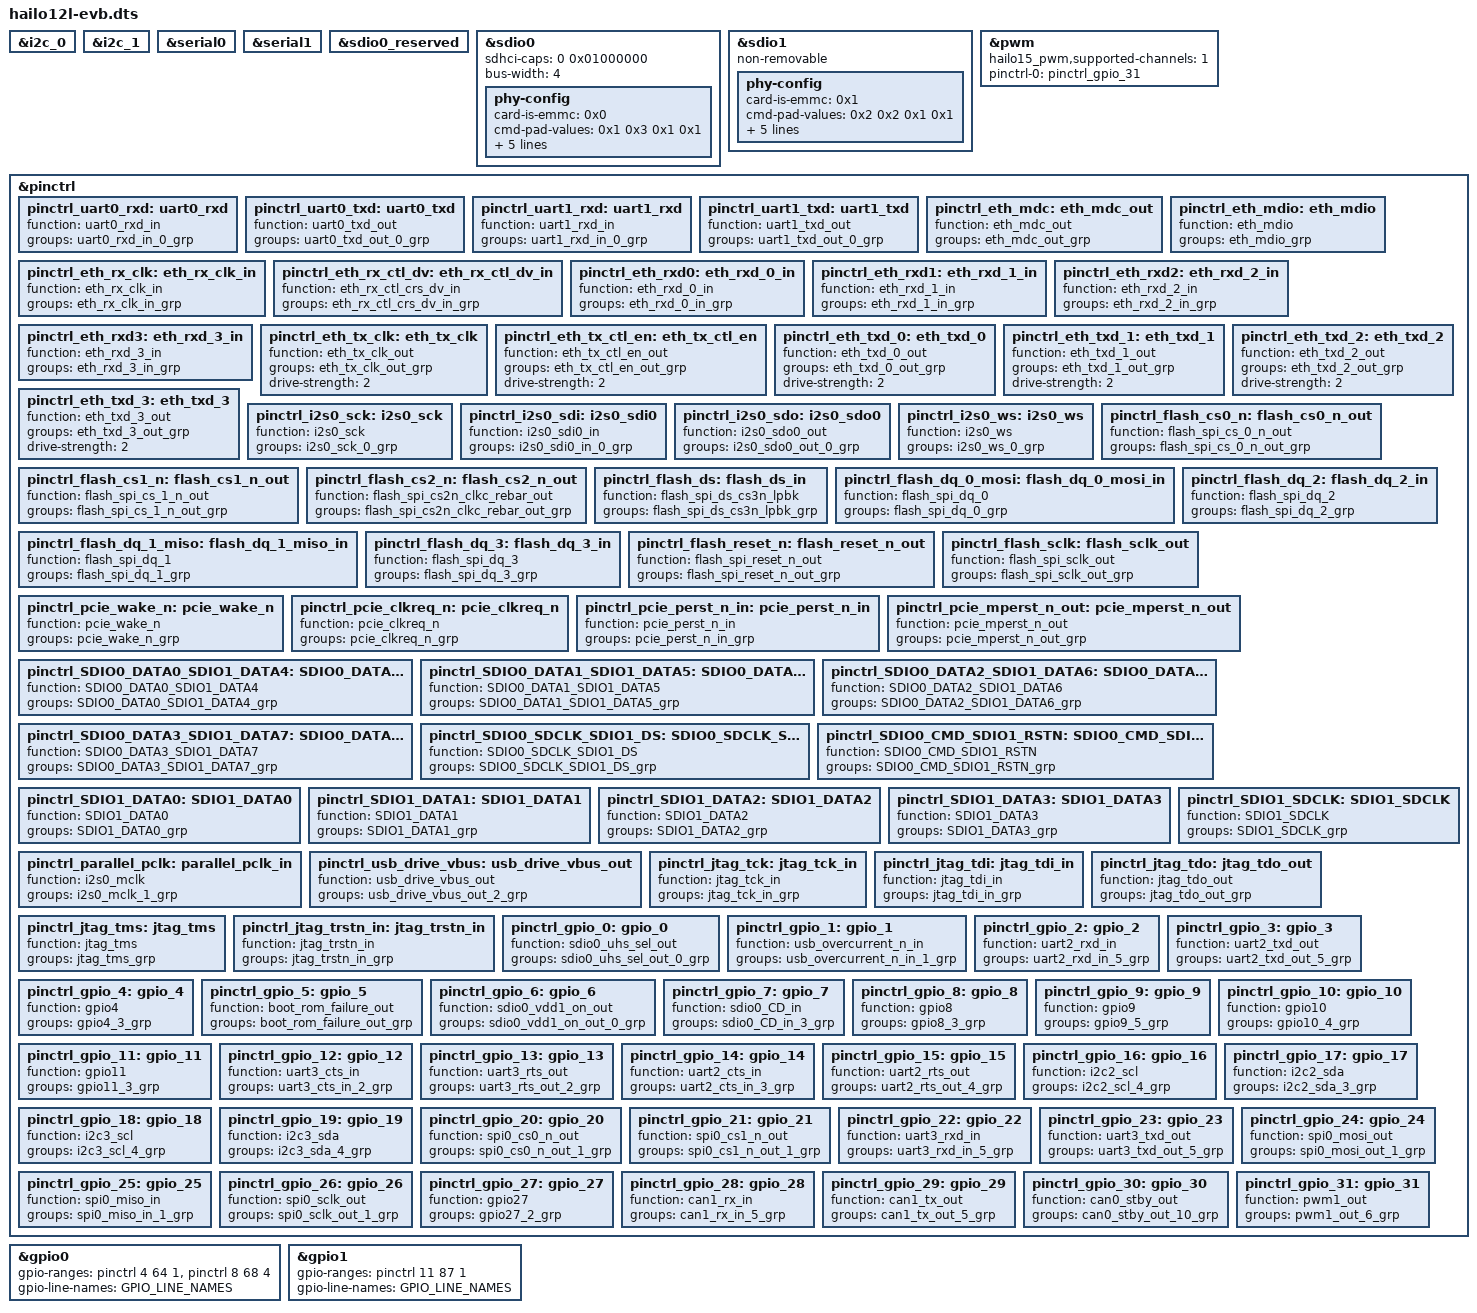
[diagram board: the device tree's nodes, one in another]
// SPDX-License-Identifier:     GPL-2.0
/*
 * Copyright (c) 2019-2025 Hailo Technologies Ltd. All rights reserved.
 */

/dts-v1/;
#include "hailo12l-base.dtsi"

&i2c_0 {
    status = "okay";
};

&i2c_1 {
    status = "okay";
};

&serial0 {
    status = "okay";
};

&serial1 {
    status = "okay";
};

&sdio0_reserved {
    status = "okay";
};

&sdio0 {
    status = "okay";
    sdhci-caps = <0 0x01000000>; // Force VOLT33 capability
    bus-width = <4>;
    phy-config {
            card-is-emmc = <0x0>;
            cmd-pad-values = <0x1 0x3 0x1 0x1>; // txslew_ctrl_n, txslew_ctrl_p, weakpull_enable, rxsel
            dat-pad-values = <0x1 0x3 0x1 0x1>; // txslew_ctrl_n, txslew_ctrl_p, weakpull_enable, rxsel
            rst-pad-values = <0x1 0x3 0x1 0x1>; // txslew_ctrl_n, txslew_ctrl_p, weakpull_enable, rxsel
            clk-pad-values = <0x1 0x3 0x0 0x1>; // txslew_ctrl_n, txslew_ctrl_p, weakpull_enable, rxsel
            sdclkdl-cnfg = <0x1 0x7F>; //extdly_en, cckdl_dc
            drive-strength = <0x9 0x8>; //pad_sp, pad_sn
    };
};

&sdio1 {
    status = "okay";
    non-removable;
    phy-config {
            card-is-emmc = <0x1>;
            cmd-pad-values = <0x2 0x2 0x1 0x1>; // txslew_ctrl_n, txslew_ctrl_p, weakpull_enable, rxsel
            dat-pad-values = <0x2 0x2 0x1 0x1>; // txslew_ctrl_n, txslew_ctrl_p, weakpull_enable, rxsel
            rst-pad-values = <0x2 0x2 0x1 0x1>; // txslew_ctrl_n, txslew_ctrl_p, weakpull_enable, rxsel
            clk-pad-values = <0x2 0x2 0x0 0x0>; // txslew_ctrl_n, txslew_ctrl_p, weakpull_enable, rxsel
            sdclkdl-cnfg = <0x1 0x59>; //extdly_en, cckdl_dc
            drive-strength = <0x9 0x8>; //pad_sp, pad_sn
            u-boot,dm-spl;
    };
};

&pwm {
    status = "okay";
    hailo15_pwm,supported-channels = <1>;
    pinctrl-names = "default";
    pinctrl-0 = <&pinctrl_gpio_31>;
};

&pinctrl {
    /* IO_PAD_0  - I2C0_SCL - non-muxable */
    /* IO_PAD_1  - I2C0_SDA - non-muxable */
    /* IO_PAD_2  - I2C1_SCL - non-muxable */
    /* IO_PAD_3  - I2C1_SDA - non-muxable */

    /* IO_PAD_4 */
    pinctrl_uart0_rxd: uart0_rxd {
        function = "uart0_rxd_in";
        groups = "uart0_rxd_in_0_grp";
    };

    /* IO_PAD_5 */
    pinctrl_uart0_txd: uart0_txd {
        function = "uart0_txd_out";
        groups = "uart0_txd_out_0_grp";
    };

    /* IO_PAD_6 */
    pinctrl_uart1_rxd: uart1_rxd {
        function = "uart1_rxd_in";
        groups = "uart1_rxd_in_0_grp";
    };

    /* IO_PAD_7 */
    pinctrl_uart1_txd: uart1_txd {
        function = "uart1_txd_out";
        groups = "uart1_txd_out_0_grp";
    };

    /* IO_PAD_8 */
    pinctrl_eth_mdc: eth_mdc_out {
        function = "eth_mdc_out";
        groups = "eth_mdc_out_grp";
    };

    /* IO_PAD_9 */
    pinctrl_eth_mdio: eth_mdio {
        function = "eth_mdio";
        groups = "eth_mdio_grp";
    };

    /* IO_PAD_10 */
    pinctrl_eth_rx_clk: eth_rx_clk_in {
        function = "eth_rx_clk_in";
        groups = "eth_rx_clk_in_grp";
    };

    /* IO_PAD_11 */
    pinctrl_eth_rx_ctl_dv: eth_rx_ctl_dv_in {
        function = "eth_rx_ctl_crs_dv_in";
        groups = "eth_rx_ctl_crs_dv_in_grp";
    };

    /* IO_PAD_12 */
    pinctrl_eth_rxd0: eth_rxd_0_in {
        function = "eth_rxd_0_in";
        groups = "eth_rxd_0_in_grp";
    };

    /* IO_PAD_13 */
    pinctrl_eth_rxd1: eth_rxd_1_in {
        function = "eth_rxd_1_in";
        groups = "eth_rxd_1_in_grp";
    };

    /* IO_PAD_14 */
    pinctrl_eth_rxd2: eth_rxd_2_in {
        function = "eth_rxd_2_in";
        groups = "eth_rxd_2_in_grp";
    };

    /* IO_PAD_15 */
    pinctrl_eth_rxd3: eth_rxd_3_in {
        function = "eth_rxd_3_in";
        groups = "eth_rxd_3_in_grp";
    };

    /* IO_PAD_16 */
    pinctrl_eth_tx_clk: eth_tx_clk {
        function = "eth_tx_clk_out";
        groups = "eth_tx_clk_out_grp";
        drive-strength = <2>;
    };

    /* IO_PAD_17 */
    pinctrl_eth_tx_ctl_en: eth_tx_ctl_en {
        function = "eth_tx_ctl_en_out";
        groups = "eth_tx_ctl_en_out_grp";
        drive-strength = <2>;
    };

    /* IO_PAD_18 */
    pinctrl_eth_txd_0: eth_txd_0 {
        function = "eth_txd_0_out";
        groups = "eth_txd_0_out_grp";
        drive-strength = <2>;
    };

    /* IO_PAD_19 */
    pinctrl_eth_txd_1: eth_txd_1 {
        function = "eth_txd_1_out";
        groups = "eth_txd_1_out_grp";
        drive-strength = <2>;
    };

    /* IO_PAD_20 */
    pinctrl_eth_txd_2: eth_txd_2 {
        function = "eth_txd_2_out";
        groups = "eth_txd_2_out_grp";
        drive-strength = <2>;
    };

    /* IO_PAD_21 */
    pinctrl_eth_txd_3: eth_txd_3 {
        function = "eth_txd_3_out";
        groups = "eth_txd_3_out_grp";
        drive-strength = <2>;
    };

    /* IO_PAD_22 */
    pinctrl_i2s0_sck: i2s0_sck {
        function = "i2s0_sck";
        groups = "i2s0_sck_0_grp";
    };

    /* IO_PAD_23 */
    pinctrl_i2s0_sdi: i2s0_sdi0 {
        function = "i2s0_sdi0_in";
        groups = "i2s0_sdi0_in_0_grp";
    };

    /* IO_PAD_24 */
    pinctrl_i2s0_sdo: i2s0_sdo0 {
        function = "i2s0_sdo0_out";
        groups = "i2s0_sdo0_out_0_grp";
    };

    /* IO_PAD_25 */
    pinctrl_i2s0_ws: i2s0_ws {
        function = "i2s0_ws";
        groups = "i2s0_ws_0_grp";
    };

    /* IO_PAD_26 */
	pinctrl_flash_cs0_n: flash_cs0_n_out {
	    function = "flash_spi_cs_0_n_out";
        groups = "flash_spi_cs_0_n_out_grp";
    };

    /* IO_PAD_27 */
    pinctrl_flash_cs1_n: flash_cs1_n_out {
	    function = "flash_spi_cs_1_n_out";
        groups = "flash_spi_cs_1_n_out_grp";
    };

    /* IO_PAD_28 */
    pinctrl_flash_cs2_n: flash_cs2_n_out {
	    function = "flash_spi_cs2n_clkc_rebar_out";
        groups = "flash_spi_cs2n_clkc_rebar_out_grp";
    };

    /* IO_PAD_29 */
    pinctrl_flash_ds: flash_ds_in {
	    function = "flash_spi_ds_cs3n_lpbk";
        groups = "flash_spi_ds_cs3n_lpbk_grp";
    };

    /* IO_PAD_30 */
    pinctrl_flash_dq_0_mosi: flash_dq_0_mosi_in {
	    function = "flash_spi_dq_0";
        groups = "flash_spi_dq_0_grp";
    };

    /* IO_PAD_31 */
    pinctrl_flash_dq_1_miso: flash_dq_1_miso_in {
	    function = "flash_spi_dq_1";
        groups = "flash_spi_dq_1_grp";
    };

    /* IO_PAD_32 */
    pinctrl_flash_dq_2: flash_dq_2_in {
	    function = "flash_spi_dq_2";
        groups = "flash_spi_dq_2_grp";
    };

    /* IO_PAD_33 */
    pinctrl_flash_dq_3: flash_dq_3_in {
	    function = "flash_spi_dq_3";
        groups = "flash_spi_dq_3_grp";
    };

    /* IO_PAD_34 */
    pinctrl_flash_reset_n: flash_reset_n_out {
	    function = "flash_spi_reset_n_out";
        groups = "flash_spi_reset_n_out_grp";
    };

    /* IO_PAD_35 */
    pinctrl_flash_sclk: flash_sclk_out {
	    function = "flash_spi_sclk_out";
        groups = "flash_spi_sclk_out_grp";
    };

    /* IO_PAD_36 */
    pinctrl_pcie_wake_n: pcie_wake_n {
        function = "pcie_wake_n";
        groups = "pcie_wake_n_grp";
    };

    /* IO_PAD_37 */
    pinctrl_pcie_clkreq_n: pcie_clkreq_n {
        function = "pcie_clkreq_n";
        groups = "pcie_clkreq_n_grp";
    };

    /* IO_PAD_38 */
    pinctrl_pcie_perst_n_in: pcie_perst_n_in {
        function = "pcie_perst_n_in";
        groups = "pcie_perst_n_in_grp";
    };

    /* IO_PAD_39 */
    pinctrl_pcie_mperst_n_out: pcie_mperst_n_out {
        function = "pcie_mperst_n_out";
        groups = "pcie_mperst_n_out_grp";
    };

    /* IO_PAD_40 */
    pinctrl_SDIO0_DATA0_SDIO1_DATA4: SDIO0_DATA0_SDIO1_DATA4 {
        function = "SDIO0_DATA0_SDIO1_DATA4";
        groups = "SDIO0_DATA0_SDIO1_DATA4_grp";
    };

    /* IO_PAD_41 */
    pinctrl_SDIO0_DATA1_SDIO1_DATA5: SDIO0_DATA1_SDIO1_DATA5 {
        function = "SDIO0_DATA1_SDIO1_DATA5";
        groups = "SDIO0_DATA1_SDIO1_DATA5_grp";
    };

    /* IO_PAD_42 */
    pinctrl_SDIO0_DATA2_SDIO1_DATA6: SDIO0_DATA2_SDIO1_DATA6 {
        function = "SDIO0_DATA2_SDIO1_DATA6";
        groups = "SDIO0_DATA2_SDIO1_DATA6_grp";
    };

    /* IO_PAD_43 */
    pinctrl_SDIO0_DATA3_SDIO1_DATA7: SDIO0_DATA3_SDIO1_DATA7 {
        function = "SDIO0_DATA3_SDIO1_DATA7";
        groups = "SDIO0_DATA3_SDIO1_DATA7_grp";
    };

    /* IO_PAD_44 */
    pinctrl_SDIO0_SDCLK_SDIO1_DS: SDIO0_SDCLK_SDIO1_DS {
        function = "SDIO0_SDCLK_SDIO1_DS";
        groups = "SDIO0_SDCLK_SDIO1_DS_grp";
    };

    /* IO_PAD_45 */
    pinctrl_SDIO0_CMD_SDIO1_RSTN: SDIO0_CMD_SDIO1_RSTN {
        function = "SDIO0_CMD_SDIO1_RSTN";
        groups = "SDIO0_CMD_SDIO1_RSTN_grp";
    };

    /* IO_PAD_46 */
    pinctrl_SDIO1_DATA0: SDIO1_DATA0 {
        function = "SDIO1_DATA0";
        groups = "SDIO1_DATA0_grp";
    };

    /* IO_PAD_47 */
    pinctrl_SDIO1_DATA1: SDIO1_DATA1 {
        function = "SDIO1_DATA1";
        groups = "SDIO1_DATA1_grp";
    };

    /* IO_PAD_48 */
    pinctrl_SDIO1_DATA2: SDIO1_DATA2 {
        function = "SDIO1_DATA2";
        groups = "SDIO1_DATA2_grp";
    };

    /* IO_PAD_49 */
    pinctrl_SDIO1_DATA3: SDIO1_DATA3 {
        function = "SDIO1_DATA3";
        groups = "SDIO1_DATA3_grp";
    };

    /* IO_PAD_50 - SDIO1_CMD - non-muxable */

    /* IO_PAD_51 */
    pinctrl_SDIO1_SDCLK: SDIO1_SDCLK {
        function = "SDIO1_SDCLK";
        groups = "SDIO1_SDCLK_grp";
    };

    /* IO_PAD_52 */
    pinctrl_parallel_pclk: parallel_pclk_in {
        function = "i2s0_mclk";
        groups = "i2s0_mclk_1_grp";
    };

    /* IO_PAD_53 */
    pinctrl_usb_drive_vbus: usb_drive_vbus_out {
        function = "usb_drive_vbus_out";
        groups = "usb_drive_vbus_out_2_grp";
    };

    /* IO_PAD_54 - SAFETY_FATAL_N - non-muxable */

    /* IO_PAD_55 */
    pinctrl_jtag_tck: jtag_tck_in {
        function = "jtag_tck_in";
        groups = "jtag_tck_in_grp";
    };

    /* IO_PAD_56 */
    pinctrl_jtag_tdi: jtag_tdi_in {
        function = "jtag_tdi_in";
        groups = "jtag_tdi_in_grp";
    };

    /* IO_PAD_57 */
    pinctrl_jtag_tdo: jtag_tdo_out {
        function = "jtag_tdo_out";
        groups = "jtag_tdo_out_grp";
    };

    /* IO_PAD_58 */
    pinctrl_jtag_tms: jtag_tms {
        function = "jtag_tms";
        groups = "jtag_tms_grp";
    };

    /* IO_PAD_59 */
    pinctrl_jtag_trstn_in: jtag_trstn_in {
        function = "jtag_trstn_in";
        groups = "jtag_trstn_in_grp";
    };

    /* IO_PAD_60 */
    pinctrl_gpio_0: gpio_0 {
        function = "sdio0_uhs_sel_out";
        groups = "sdio0_uhs_sel_out_0_grp";
    };

    /* IO_PAD_61 */
    pinctrl_gpio_1: gpio_1 {
        function = "usb_overcurrent_n_in";
        groups = "usb_overcurrent_n_in_1_grp";
    };

    /* IO_PAD_62 */
    pinctrl_gpio_2: gpio_2 {
        function = "uart2_rxd_in";
        groups = "uart2_rxd_in_5_grp";
    };

    /* IO_PAD_63 */
    pinctrl_gpio_3: gpio_3 {
        function = "uart2_txd_out";
        groups = "uart2_txd_out_5_grp";
    };

    /* IO_PAD_64 - GPIO_4 - In EVB, gpio 4 pin is serving as gpio function, and connected to DSI for DSI interrupt */
    pinctrl_gpio_4: gpio_4 {
        function = "gpio4";
        groups = "gpio4_3_grp";
    };

    /* IO_PAD_65 */
    pinctrl_gpio_5: gpio_5 {
        function = "boot_rom_failure_out";
        groups = "boot_rom_failure_out_grp";
    };

    /* IO_PAD_66 */
    pinctrl_gpio_6: gpio_6 {
        function = "sdio0_vdd1_on_out";
        groups = "sdio0_vdd1_on_out_0_grp";
    };

    /* IO_PAD_67 */
    pinctrl_gpio_7: gpio_7 {
        function = "sdio0_CD_in";
        groups = "sdio0_CD_in_3_grp";
    };

    /* IO_PAD_68 - GPIO_8 - In EVB, gpio 8 pin is serving as gpio function, and connected to sensor 1 for sensor 1 reset */
    pinctrl_gpio_8: gpio_8 {
        function = "gpio8";
        groups = "gpio8_3_grp";
    };

    /* IO_PAD_68 - GPIO_9 - In EVB, gpio 9 pin is serving as gpio function, and connected to sensor 0 for sensor 0 reset */
    pinctrl_gpio_9: gpio_9 {
        function = "gpio9";
        groups = "gpio9_5_grp";
    };

    /* IO_PAD_70 - GPIO_10 - In EVB, gpio 10 pin is serving as gpio function, and connected to connectivity socket for uart wake function  */
    pinctrl_gpio_10: gpio_10 {
        function = "gpio10";
        groups = "gpio10_4_grp";
    };

    /* IO_PAD_71 - GPIO_11 - In EVB, gpio 11 pin is serving as gpio function, and connected to power circuit for shutdown function  */
    pinctrl_gpio_11: gpio_11 {
        function = "gpio11";
        groups = "gpio11_3_grp";
    };

    /* IO_PAD_72 */
    pinctrl_gpio_12: gpio_12 {
        function = "uart3_cts_in";
        groups = "uart3_cts_in_2_grp";
    };

    /* IO_PAD_73 */
    pinctrl_gpio_13: gpio_13 {
        function = "uart3_rts_out";
        groups = "uart3_rts_out_2_grp";
    };

    /* IO_PAD_74 */
    pinctrl_gpio_14: gpio_14 {
        function = "uart2_cts_in";
        groups = "uart2_cts_in_3_grp";
    };

    /* IO_PAD_75 */
    pinctrl_gpio_15: gpio_15 {
        function = "uart2_rts_out";
        groups = "uart2_rts_out_4_grp";
    };

    /* IO_PAD_76 */
    pinctrl_gpio_16: gpio_16 {
        function = "i2c2_scl";
        groups = "i2c2_scl_4_grp";
    };

    /* IO_PAD_77 */
    pinctrl_gpio_17: gpio_17 {
        function = "i2c2_sda";
        groups = "i2c2_sda_3_grp";
    };

    /* IO_PAD_78 */
    pinctrl_gpio_18: gpio_18 {
        function = "i2c3_scl";
        groups = "i2c3_scl_4_grp";
    };

    /* IO_PAD_79 */
    pinctrl_gpio_19: gpio_19 {
        function = "i2c3_sda";
        groups = "i2c3_sda_4_grp";
    };

    /* IO_PAD_80 */
    pinctrl_gpio_20: gpio_20 {
        function = "spi0_cs0_n_out";
        groups = "spi0_cs0_n_out_1_grp";
    };

    /* IO_PAD_81 */
    pinctrl_gpio_21: gpio_21 {
        function = "spi0_cs1_n_out";
        groups = "spi0_cs1_n_out_1_grp";
    };

    /* IO_PAD_82 */
    pinctrl_gpio_22: gpio_22 {
        function = "uart3_rxd_in";
        groups = "uart3_rxd_in_5_grp";
    };

    /* IO_PAD_83 */
    pinctrl_gpio_23: gpio_23 {
        function = "uart3_txd_out";
        groups = "uart3_txd_out_5_grp";
    };

    /* IO_PAD_84 */
    pinctrl_gpio_24: gpio_24 {
        function = "spi0_mosi_out";
        groups = "spi0_mosi_out_1_grp";
    };

    /* IO_PAD_85 */
    pinctrl_gpio_25: gpio_25 {
        function = "spi0_miso_in";
        groups = "spi0_miso_in_1_grp";
    };

    /* IO_PAD_86 */
    pinctrl_gpio_26: gpio_26 {
        function = "spi0_sclk_out";
        groups = "spi0_sclk_out_1_grp";
    };

    /* IO_PAD_87 - GPIO_27 - In EVB, gpio 27 pin is serving as gpio function, and connected to GP header for cold reset function */
    pinctrl_gpio_27: gpio_27 {
        function = "gpio27";
        groups = "gpio27_2_grp";
    };

    /* IO_PAD_88 */
    pinctrl_gpio_28: gpio_28 {
        function = "can1_rx_in";
        groups = "can1_rx_in_5_grp";
    };

    /* IO_PAD_89 */
    pinctrl_gpio_29: gpio_29 {
        function = "can1_tx_out";
        groups = "can1_tx_out_5_grp";
    };

    /* IO_PAD_90 */
    pinctrl_gpio_30: gpio_30 {
        function = "can0_stby_out";
        groups = "can0_stby_out_10_grp";
    };

    /* IO_PAD_91 */
    pinctrl_gpio_31: gpio_31 {
        function = "pwm1_out";
        groups = "pwm1_out_6_grp";
    };
};

#define GPIO_LINE_NAMES \
    "",                         "",                     "",                         "", \
    "gpio_4 - dsi_interrupt",   "",                     "",                         "", \
    "gpio_8 - sensor1_reset",   "gpio_9 - sensor0 reset","gpio_10 - uart_wake_n",    "gpio_11 - shutdown", \
    "",                         "",                     "",                         "", \
    \
    "",                         "",                     "",                         "", \
    "",                         "",                     "",                         "", \
    "",                         "",                     "",                         "gpio_27 - cold_reset", \
    "",                         "",                     "",                         ""


&gpio0 {
    /* The format of gpio-ranges is: <[pin controller phandle], [GPIO controller offset],
                [pin controller offset], [number of pins]>;
    */
    gpio-ranges = <&pinctrl 4 64 1>,
                  <&pinctrl 8 68 4>;

    gpio-line-names = GPIO_LINE_NAMES;
};

&gpio1 {
    gpio-ranges = <&pinctrl 11 87 1>;

    gpio-line-names = GPIO_LINE_NAMES;
};
